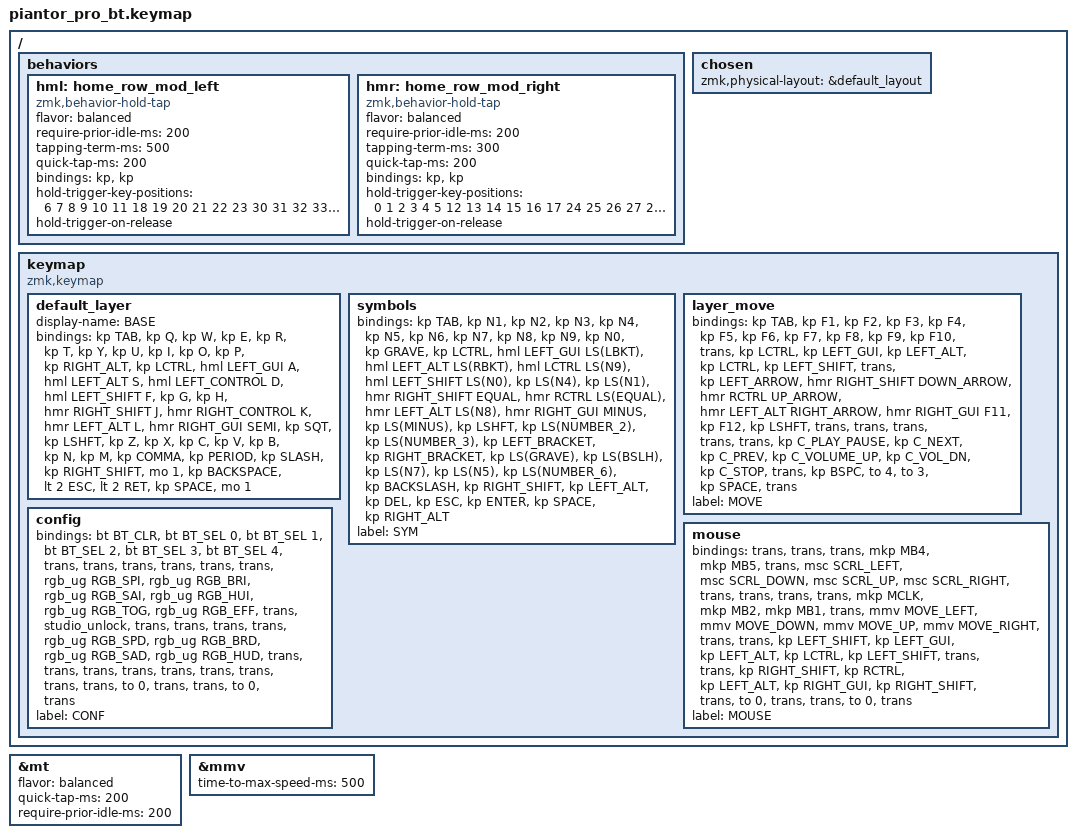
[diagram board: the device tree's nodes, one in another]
/*
 * Copyright (c) 2020 The ZMK Contributors
 *
 * SPDX-License-Identifier: MIT
 */

#define ZMK_POINTING_DEFAULT_MOVE_VAL 3000  // default: 600
#define ZMK_POINTING_DEFAULT_SCRL_VAL 20    // default: 10

#include <behaviors.dtsi>
#include <dt-bindings/zmk/bt.h>
#include <dt-bindings/zmk/keys.h>
#include <dt-bindings/zmk/pointing.h>
#include <dt-bindings/zmk/rgb.h>

&mt {
    flavor = "balanced";
    quick-tap-ms = <200>;
    require-prior-idle-ms = <200>;
};

&mmv { time-to-max-speed-ms = <500>; };

/ {
    behaviors {
        hml: home_row_mod_left {
            compatible = "zmk,behavior-hold-tap";
            #binding-cells = <2>;
            flavor = "balanced";
            require-prior-idle-ms = <200>;
            tapping-term-ms = <500>;
            quick-tap-ms = <200>;
            bindings = <&kp>, <&kp>;

            hold-trigger-key-positions = <6 7 8 9 10 11 18 19 20 21 22 23 30 31 32 33 34 35 36 37 38 39 40 41>;
            hold-trigger-on-release;
        };

        hmr: home_row_mod_right {
            compatible = "zmk,behavior-hold-tap";
            #binding-cells = <2>;
            flavor = "balanced";
            require-prior-idle-ms = <200>;
            tapping-term-ms = <300>;
            quick-tap-ms = <200>;
            bindings = <&kp>, <&kp>;

            hold-trigger-key-positions = <0 1 2 3 4 5 12 13 14 15 16 17 24 25 26 27 28 29 36 37 38 39 40 41>;
            hold-trigger-on-release;
        };
    };
};

/ {
    chosen { zmk,physical-layout = &default_layout; };
};

/ {
    keymap {
        compatible = "zmk,keymap";

        default_layer {
            display-name = "BASE";

            // --------------------------------------------------------------------------------
            // |  TAB |  Q  |  W  |  E  |  R  |  T  |  Y  |  U   |  I  |  O  |  P  | BSPC |
            // | CTRL |  A  |  S  |  D  |  F  |  G  |  H  |  J   |  K  |  L  |  ;  |  '   |
            // | SHFT |  Z  |  X  |  C  |  V  |  B  |  N  |  M   |  ,  |  .  |  /  | ESC  |
            //                    | GUI | LWR | SPC | ENT | RSE  | ALT |

            bindings = <
&kp TAB  &kp Q  &kp W  &kp E  &kp R  &kp T  &kp Y  &kp U  &kp I  &kp O  &kp P  &kp RIGHT_ALT  &kp LCTRL  &hml LEFT_GUI A  &hml LEFT_ALT S  &hml LEFT_CONTROL D  &hml LEFT_SHIFT F  &kp G  &kp H  &hmr RIGHT_SHIFT J  &hmr RIGHT_CONTROL K  &hmr LEFT_ALT L  &hmr RIGHT_GUI SEMI  &kp SQT  &kp LSHFT  &kp Z  &kp X  &kp C  &kp V  &kp B  &kp N  &kp M  &kp COMMA  &kp PERIOD  &kp SLASH  &kp RIGHT_SHIFT  &mo 1  &kp BACKSPACE  &lt 2 ESC  &lt 2 RET  &kp SPACE  &mo 1
            >;
        };

        symbols {
            bindings = <
&kp TAB  &kp N1  &kp N2  &kp N3  &kp N4  &kp N5  &kp N6  &kp N7  &kp N8  &kp N9  &kp N0  &kp GRAVE  &kp LCTRL  &hml LEFT_GUI LS(LBKT)  &hml LEFT_ALT LS(RBKT)  &hml LCTRL LS(N9)  &hml LEFT_SHIFT LS(N0)  &kp LS(N4)  &kp LS(N1)  &hmr RIGHT_SHIFT EQUAL  &hmr RCTRL LS(EQUAL)  &hmr LEFT_ALT LS(N8)  &hmr RIGHT_GUI MINUS  &kp LS(MINUS)  &kp LSHFT  &kp LS(NUMBER_2)  &kp LS(NUMBER_3)  &kp LEFT_BRACKET  &kp RIGHT_BRACKET  &kp LS(GRAVE)  &kp LS(BSLH)  &kp LS(N7)  &kp LS(N5)  &kp LS(NUMBER_6)  &kp BACKSLASH  &kp RIGHT_SHIFT  &kp LEFT_ALT  &kp DEL  &kp ESC  &kp ENTER  &kp SPACE  &kp RIGHT_ALT
            >;

            label = "SYM";
        };

        layer_move {
            bindings = <
&kp TAB  &kp F1  &kp F2  &kp F3  &kp F4  &kp F5  &kp F6  &kp F7  &kp F8  &kp F9  &kp F10  &trans  &kp LCTRL  &kp LEFT_GUI  &kp LEFT_ALT  &kp LCTRL  &kp LEFT_SHIFT  &trans  &kp LEFT_ARROW  &hmr RIGHT_SHIFT DOWN_ARROW  &hmr RCTRL UP_ARROW  &hmr LEFT_ALT RIGHT_ARROW  &hmr RIGHT_GUI F11  &kp F12  &kp LSHFT  &trans  &trans  &trans  &trans  &trans  &kp C_PLAY_PAUSE  &kp C_NEXT  &kp C_PREV  &kp C_VOLUME_UP  &kp C_VOL_DN  &kp C_STOP  &trans  &kp BSPC  &to 4  &to 3  &kp SPACE  &trans
            >;

            label = "MOVE";
        };

        mouse {
            bindings = <
&trans  &trans  &trans  &mkp MB4  &mkp MB5  &trans  &msc SCRL_LEFT  &msc SCRL_DOWN  &msc SCRL_UP  &msc SCRL_RIGHT  &trans  &trans  &trans  &trans  &mkp MCLK  &mkp MB2  &mkp MB1  &trans  &mmv MOVE_LEFT  &mmv MOVE_DOWN  &mmv MOVE_UP  &mmv MOVE_RIGHT  &trans  &trans  &kp LEFT_SHIFT  &kp LEFT_GUI  &kp LEFT_ALT  &kp LCTRL  &kp LEFT_SHIFT  &trans  &trans  &kp RIGHT_SHIFT  &kp RCTRL  &kp LEFT_ALT  &kp RIGHT_GUI  &kp RIGHT_SHIFT  &trans  &to 0  &trans  &trans  &to 0  &trans
            >;

            label = "MOUSE";
        };

        config {
            bindings = <
&bt BT_CLR  &bt BT_SEL 0  &bt BT_SEL 1  &bt BT_SEL 2  &bt BT_SEL 3  &bt BT_SEL 4  &trans  &trans  &trans  &trans  &trans  &trans  &rgb_ug RGB_SPI  &rgb_ug RGB_BRI  &rgb_ug RGB_SAI  &rgb_ug RGB_HUI  &rgb_ug RGB_TOG  &rgb_ug RGB_EFF  &trans  &studio_unlock  &trans  &trans  &trans  &trans  &rgb_ug RGB_SPD  &rgb_ug RGB_BRD  &rgb_ug RGB_SAD  &rgb_ug RGB_HUD  &trans  &trans  &trans  &trans  &trans  &trans  &trans  &trans  &trans  &to 0  &trans  &trans  &to 0  &trans
            >;

            label = "CONF";
        };
    };
};
